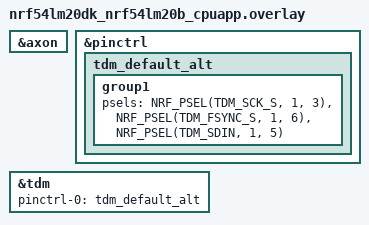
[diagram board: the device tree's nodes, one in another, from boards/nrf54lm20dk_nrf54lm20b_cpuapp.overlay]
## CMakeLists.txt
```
#
# Copyright (c) 2026 Nordic Semiconductor ASA
#
# SPDX-License-Identifier: LicenseRef-Nordic-5-Clause
#

cmake_minimum_required(VERSION 3.20.0)

# Zephyr CMake project
find_package(Zephyr REQUIRED HINTS $ENV{ZEPHYR_BASE})
project(hello_axon)

# Source files
target_sources(app PRIVATE
    src/main.c
    src/fft_chroma.c
    ../../../applications/ww_kws/src/i2s_audio.c
)
target_include_directories(app PRIVATE ../../../applications/ww_kws/src)
target_compile_definitions(app PRIVATE CONFIG_APP_AUDIO_I2S_CHANNEL=0)
```

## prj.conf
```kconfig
#
# Copyright (c) 2026 Nordic Semiconductor ASA
#
# SPDX-License-Identifier: LicenseRef-Nordic-5-Clause
#

CONFIG_NCS_SAMPLES_DEFAULTS=y

CONFIG_NRF_AXON=y

# set size of interlayer buffer to fit largest model
CONFIG_NRF_AXON_INTERLAYER_BUFFER_SIZE=8064

# set size of psum buffer to fit largest model
CONFIG_NRF_AXON_PSUM_BUFFER_SIZE=0

# Allow floating point in printf
CONFIG_PICOLIBC_IO_FLOAT=y
CONFIG_I2S=y
CONFIG_CMSIS_DSP=y
CONFIG_CMSIS_DSP_FILTERING=y
CONFIG_CMSIS_DSP_TRANSFORM=y
```

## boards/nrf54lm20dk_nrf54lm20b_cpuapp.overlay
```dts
/*
 * Copyright (c) 2026 Nordic Semiconductor ASA
 *
 * SPDX-License-Identifier: LicenseRef-Nordic-5-Clause
 */

&axon {
	status = "okay";
};

&pinctrl {
	tdm_default_alt: tdm_default_alt {
		group1 {
			psels = <NRF_PSEL(TDM_SCK_S, 1, 3)>,
				<NRF_PSEL(TDM_FSYNC_S, 1, 6)>,
				<NRF_PSEL(TDM_SDIN, 1, 5)>;
		};
	};
};

i2s_rx: &tdm {
	status = "okay";
	pinctrl-0 = <&tdm_default_alt>;
	pinctrl-names = "default";
};
```

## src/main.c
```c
/*
 * Copyright (c) 2026 Nordic Semiconductor ASA
 *
 * SPDX-License-Identifier: LicenseRef-Nordic-5-Clause
 */

#include <drivers/axon/nrf_axon_driver.h>
#include <drivers/axon/nrf_axon_nn_infer.h>
#include <axon/nrf_axon_platform.h>
#include <zephyr/kernel.h>
#include <zephyr/logging/log.h>
#include <zephyr/sys/util.h>
#include <math.h>

#include "fft_chroma.h"
#include "i2s_audio.h"
#include "generated/nrf_axon_model_guitar_note_cnn_.h"
#include "generated/nrf_axon_model_guitar_note_cnn_test_vectors_.h"
LOG_MODULE_REGISTER(guitar_note_test);

#define OUTPUT_SIZE (12)
#define LIVE_REPORT_INTERVAL_MS 200

/* From artifacts/note_cnn_fft/postprocess.json: sigmoid(logit) >= 0.45. */
#define NOTE_LOGIT_THRESHOLD (-0.20067f)

static const char *const note_names[OUTPUT_SIZE] = {
	"C", "C#", "D", "D#", "E", "F", "F#", "G", "G#", "A", "A#", "B",
};

static void format_notes(const int32_t *logits, int32_t threshold, char *buf, size_t len)
{
	size_t used = 0;

	buf[0] = '\0';
	for (size_t i = 0; i < OUTPUT_SIZE; i++) {
		if (logits[i] >= threshold) {
			used += snprintk(buf + used, len - used, "%s%s", used ? " " : "",
					 note_names[i]);
		}
	}
	if (used == 0) {
		snprintk(buf, len, "none");
	}
}

static void sync_flow(void)
{
	nrf_axon_result_e result;
	/* Raw int32 outputs are logits scaled by 2^output_dequant_round. */
	const int32_t threshold = (int32_t)(NOTE_LOGIT_THRESHOLD *
					    (float)(1 << model_guitar_note_cnn.output_dequant_round));

	result = nrf_axon_nn_model_validate(&model_guitar_note_cnn);
	if (result != NRF_AXON_RESULT_SUCCESS) {
		LOG_ERR("Model validation failed, err %d", result);
		return;
	}

	LOG_INF("Validated compiled model; running %u test vectors, raw threshold %d",
		ARRAY_SIZE(guitar_note_cnn_input_test_vectors), threshold);

	for (size_t vector = 0; vector < ARRAY_SIZE(guitar_note_cnn_input_test_vectors); vector++) {
		const int8_t *input = (const int8_t *)guitar_note_cnn_input_test_vectors[vector];
		const int32_t *expected = guitar_note_cnn_expected_output_vectors[vector];
		int32_t output[OUTPUT_SIZE];
		char detected[48];
		char reference[48];
		int32_t max_abs_diff = 0;
		uint32_t start = k_cycle_get_32();

		result = nrf_axon_nn_model_infer_sync(&model_guitar_note_cnn, input,
						       (int8_t *)output);
		uint32_t cycles = k_cycle_get_32() - start;

		if (result != NRF_AXON_RESULT_SUCCESS) {
			LOG_ERR("Inference failed for vector %u, err %d", vector, result);
			return;
		}

		for (size_t i = 0; i < OUTPUT_SIZE; i++) {
			const int32_t diff = output[i] - expected[i];

			max_abs_diff = MAX(max_abs_diff, diff < 0 ? -diff : diff);
		}
		format_notes(output, threshold, detected, sizeof(detected));
		format_notes(expected, threshold, reference, sizeof(reference));

		LOG_INF("vector %u: notes [%s], reference [%s], max abs diff %d, %u us", vector,
			detected, reference, max_abs_diff,
			k_cyc_to_us_floor32(cycles));
	}
}

static int8_t live_features[CHROMA_FRAMES][CHROMA_CLASSES];

static void live_flow(void)
{
	const int32_t threshold = (int32_t)(NOTE_LOGIT_THRESHOLD *
					    (float)(1 << model_guitar_note_cnn.output_dequant_round));
	int err = fft_chroma_init();

	if (err) {
		LOG_ERR("FFT init failed: %d", err);
		return;
	}
	err = i2s_audio_init();
	if (err) {
		LOG_ERR("I2S init failed: %d", err);
		return;
	}
	LOG_INF("Live PCM1808 -> FIR /6 -> 4096-point FFT chroma -> Axon started");
	uint32_t started_ms = k_uptime_get_32();
	uint32_t next_report_ms = started_ms + LIVE_REPORT_INTERVAL_MS;

	for (;;) {
		void *block;
		size_t size;

		err = i2s_audio_read(&block, &size, 1000);
		if (err) {
			LOG_ERR("I2S read failed: %d", err);
			return;
		}
		bool ready = fft_chroma_feed(block, size / sizeof(int16_t));

		free_i2s_audio_buffer(block);
		if (!ready) {
			continue;
		}
		uint32_t rms_squared;

		if (!fft_chroma_features(live_features, &rms_squared)) {
			continue;
		}
		int32_t logits[OUTPUT_SIZE];
		nrf_axon_result_e result = nrf_axon_nn_model_infer_sync(
			&model_guitar_note_cnn, (const int8_t *)live_features, (int8_t *)logits);
		if (result != NRF_AXON_RESULT_SUCCESS) {
			LOG_ERR("Live inference failed: %d", result);
			return;
		}
		char notes[48];

		if (rms_squared < 340) {
			snprintk(notes, sizeof(notes), "none");
		} else {
			format_notes(logits, threshold, notes, sizeof(notes));
		}
		uint32_t now_ms = k_uptime_get_32();

		if ((int32_t)(now_ms - next_report_ms) >= 0) {
			LOG_INF("live t=%u ms: [%s] rms=%u", now_ms - started_ms, notes,
				(uint32_t)sqrtf((float)rms_squared));
			/* Keep the cadence tied to uptime rather than accumulating logging delays. */
			do {
				next_report_ms += LIVE_REPORT_INTERVAL_MS;
			} while ((int32_t)(now_ms - next_report_ms) >= 0);
		}
	}
}

int main(void)
{
	nrf_axon_result_e result;
	int err;

	LOG_INF("Hello Axon sample");
	LOG_INF("Initializing Axon NPU");

	__ASSERT(model_guitar_note_cnn.inputs[model_guitar_note_cnn.external_input_ndx]
				 .dimensions.byte_width == 1,
		 "Model input data type different than expected");
	__ASSERT(model_guitar_note_cnn.output_dimensions.byte_width == 4,
		 "Model output data type different than expected");

	result = nrf_axon_platform_init();
	if (result != NRF_AXON_RESULT_SUCCESS) {
		LOG_ERR("Axon NPU platform initialization failed, err %d", result);
		return -1;
	}

	/* This model has no persistent variables, so this initialization is a no-op. */
	err = nrf_axon_nn_model_init_vars(&model_guitar_note_cnn);
	if (err) {
		LOG_ERR("Model persistent variables initialization failed, err %d", err);
		return -1;
	}

	sync_flow();
	live_flow();

	return 0;
}
```

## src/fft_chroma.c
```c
#include "fft_chroma.h"

#include <arm_math.h>
#include <math.h>
#include <string.h>

#define RATE 16000
#define MIN_HZ 65.0f
#define MAX_HZ 2093.0f
#define INPUT_ZERO (-128)
#define QUANT_GAIN_NUM 1000000ULL
#define QUANT_GAIN_DEN 3683ULL

static arm_rfft_instance_q15 fft;
static q15_t ring[CHROMA_FFT_SIZE];
static q15_t window[CHROMA_FFT_SIZE];
static q15_t fft_input[CHROMA_FFT_SIZE];
static q15_t fft_output[2 * CHROMA_FFT_SIZE];
static int8_t bin_pitch[CHROMA_FFT_SIZE / 2 + 1];
static int8_t history[CHROMA_FRAMES][CHROMA_CLASSES];
static uint32_t squared_history[CHROMA_FRAMES];
static unsigned int write_at;
static unsigned int sample_count;
static unsigned int hop_count;
static unsigned int frame_count;

static uint64_t sqrt_u64(uint64_t value)
{
	uint64_t root = 0;
	uint64_t bit = 1ULL << 62;

	while (bit > value) {
		bit >>= 2;
	}
	while (bit) {
		if (value >= root + bit) {
			value -= root + bit;
			root = (root >> 1) + bit;
		} else {
			root >>= 1;
		}
		bit >>= 2;
	}
	return root;
}

int fft_chroma_init(void)
{
	if (arm_rfft_init_q15(&fft, CHROMA_FFT_SIZE, 0, 1) != ARM_MATH_SUCCESS) {
		return -1;
	}

	for (unsigned int i = 0; i < CHROMA_FFT_SIZE; ++i) {
		float hann = 0.5f * (1.0f - cosf(2.0f * PI * i / CHROMA_FFT_SIZE));

		window[i] = (q15_t)lroundf(32767.0f * hann);
	}
	for (unsigned int i = 0; i <= CHROMA_FFT_SIZE / 2; ++i) {
		float hz = (float)i * RATE / CHROMA_FFT_SIZE;

		bin_pitch[i] = -1;
		if (hz < MIN_HZ || hz > MAX_HZ) {
			continue;
		}
		float pitch = 69.0f + 12.0f * log2f(hz / 440.0f);
		int nearest = (int)lroundf(pitch);

		if (fabsf(pitch - nearest) < 0.5f) {
			bin_pitch[i] = (int8_t)((nearest % 12 + 12) % 12);
		}
	}
	memset(ring, 0, sizeof(ring));
	memset(history, INPUT_ZERO, sizeof(history));
	write_at = sample_count = hop_count = frame_count = 0;
	return 0;
}

static void calculate_frame(void)
{
	uint32_t energies[CHROMA_CLASSES] = {0};
	uint64_t square_sum = 0;
	unsigned int slot = frame_count % CHROMA_FRAMES;

	for (unsigned int i = 0; i < CHROMA_FFT_SIZE; ++i) {
		int32_t v = ring[(write_at + i) % CHROMA_FFT_SIZE];

		square_sum += (int64_t)v * v;
		fft_input[i] = (q15_t)((v * window[i]) >> 15);
	}
	arm_rfft_q15(&fft, fft_input, fft_output);
	for (unsigned int i = 0; i <= CHROMA_FFT_SIZE / 2; ++i) {
		int pc = bin_pitch[i];

		if (pc < 0) {
			continue;
		}
		int32_t real = fft_output[2 * i];
		int32_t imag = fft_output[2 * i + 1];

		energies[pc] += (uint32_t)sqrt_u64((uint64_t)(real * real + imag * imag));
	}

	uint64_t norm2 = 0;

	for (unsigned int p = 0; p < CHROMA_CLASSES; ++p) {
		norm2 += (uint64_t)energies[p] * energies[p];
	}
	uint64_t denom = sqrt_u64(norm2) * QUANT_GAIN_DEN;

	for (unsigned int p = 0; p < CHROMA_CLASSES; ++p) {
		int value = INPUT_ZERO;

		if (denom != 0) {
			value += (int)(((uint64_t)energies[p] * QUANT_GAIN_NUM + denom / 2) /
				       denom);
		}

		history[slot][p] = (int8_t)(value < -128 ? -128 : value > 127 ? 127 : value);
	}
	squared_history[slot] = (uint32_t)(square_sum / CHROMA_FFT_SIZE);
	++frame_count;
}

bool fft_chroma_feed(const int16_t *audio, unsigned int count)
{
	bool ready = false;

	for (unsigned int i = 0; i < count; ++i) {
		ring[write_at] = audio[i];
		write_at = (write_at + 1) % CHROMA_FFT_SIZE;
		++sample_count;
		if (++hop_count == CHROMA_HOP) {
			hop_count = 0;
			if (sample_count >= CHROMA_FFT_SIZE) {
				calculate_frame();
				ready = true;
			}
		}
	}
	return ready;
}

bool fft_chroma_features(int8_t output[CHROMA_FRAMES][CHROMA_CLASSES],
			 uint32_t *rms_squared)
{
	if (frame_count < CHROMA_FRAMES) {
		return false;
	}
	for (unsigned int i = 0; i < CHROMA_FRAMES; ++i) {
		unsigned int slot = (frame_count + i) % CHROMA_FRAMES;

		memcpy(output[i], history[slot], CHROMA_CLASSES);
	}
	*rms_squared = squared_history[(frame_count - 1) % CHROMA_FRAMES];
	return true;
}
```

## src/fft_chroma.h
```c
#ifndef FFT_CHROMA_H_
#define FFT_CHROMA_H_

#include <stdbool.h>
#include <stdint.h>

#define CHROMA_FFT_SIZE 4096
#define CHROMA_HOP 320
#define CHROMA_FRAMES 32
#define CHROMA_CLASSES 12

int fft_chroma_init(void);
/* Feed 16 kHz mono signed PCM. Returns true whenever a new 20 ms frame is ready. */
bool fft_chroma_feed(const int16_t *audio, unsigned int count);
/* Copy chronological [32][12] quantized features; valid after 32 frames. */
bool fft_chroma_features(int8_t output[CHROMA_FRAMES][CHROMA_CLASSES],
			 uint32_t *rms_squared);

#endif
```
